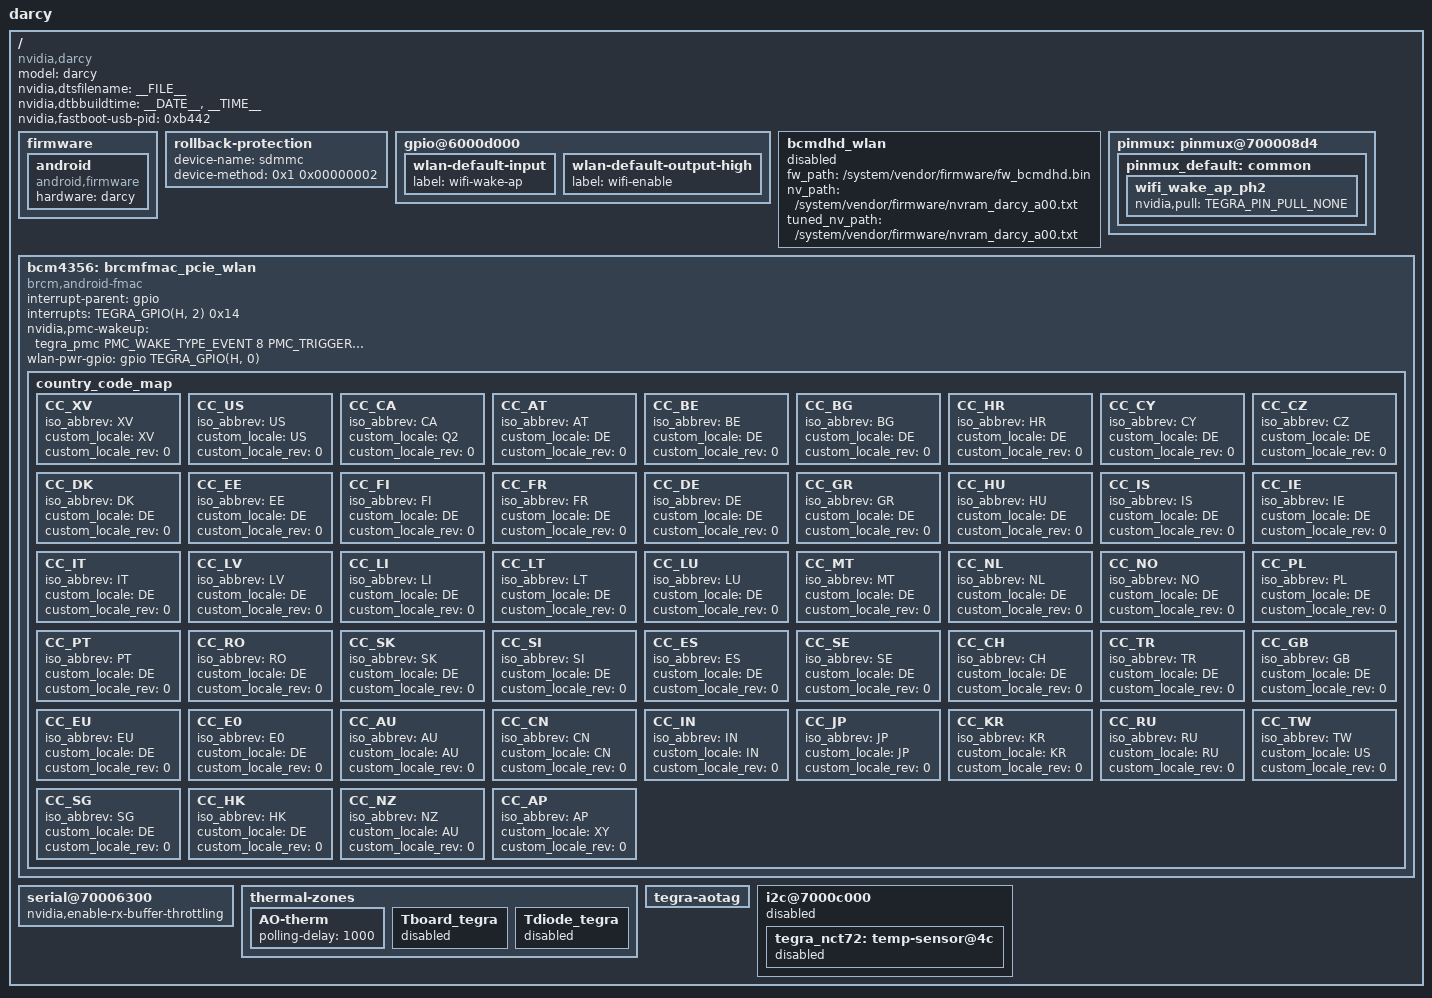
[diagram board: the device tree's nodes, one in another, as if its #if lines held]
/*
 * arch/arm64/boot/dts/tegra210b01-darcy-p2894-2551-b00-00.dts
 *
 * Copyright (c) 2018, NVIDIA CORPORATION.  All rights reserved.
 *
 * This program is free software; you can redistribute it and/or modify
 * it under the terms of the GNU General Public License as published by
 * the Free Software Foundation; version 2 of the License.
 *
 * This program is distributed in the hope that it will be useful, but WITHOUT
 * ANY WARRANTY; without even the implied warranty of MERCHANTABILITY or
 * FITNESS FOR A PARTICULAR PURPOSE.  See the GNU General Public License for
 * more details.
 *
 * You should have received a copy of the GNU General Public License along
 * with this program; if not, write to the Free Software Foundation, Inc.,
 * 51 Franklin Street, Fifth Floor, Boston, MA  02110-1301, USA.
 *
 */
#include "tegra210b01-darcy-p2894-common.dtsi"
#include "foster-platforms/tegra210-darcy-pinmux-p2894-0000-a00.dtsi"
#include "darcy-platforms/tegra210b01-darcy-power-tree-p2894-0000-a00.dtsi"
#include "darcy-platforms/tegra210b01-darcy-extcon-p2894-0000-a00.dtsi"
#include "darcy-platforms/tegra210b01-darcy-pcie.dtsi"

/ {
	model = "darcy";
	compatible = "nvidia,darcy", "nvidia,foster-e", "nvidia,tegra210b01";
	nvidia,dtsfilename = __FILE__;
	nvidia,dtbbuildtime = __DATE__, __TIME__;
	nvidia,fastboot-usb-pid = <0xb442>;

	firmware {
		android {
			compatible = "android,firmware";
			hardware = "darcy";
		};
	};

	rollback-protection {
		device-name = "sdmmc";
		device-method = <0x1 0x00000002>; /* type (0x1 = ioctl), argument */
		status = "okay";
	};

	gpio@6000d000 {
		wlan-default-input {
			label = "wifi-wake-ap";
		};
		wlan-default-output-high {
			label = "wifi-enable";
		};
	};

	bcmdhd_wlan {
		fw_path = "/system/vendor/firmware/fw_bcmdhd.bin";
		nv_path = "/system/vendor/firmware/nvram_darcy_a00.txt";
		tuned_nv_path = "/system/vendor/firmware/nvram_darcy_a00.txt";
		status = "disabled";
	};

	pinmux: pinmux@700008d4 {
		pinmux_default: common {
			wifi_wake_ap_ph2 {
				nvidia,pull = <TEGRA_PIN_PULL_NONE>;
			};
		};
	};

	bcm4356: brcmfmac_pcie_wlan {
		compatible = "brcm,android-fmac";
		interrupt-parent = <&gpio>;
		interrupts = <TEGRA_GPIO(H, 2) 0x14>;
		nvidia,pmc-wakeup = <&tegra_pmc
		PMC_WAKE_TYPE_EVENT 8 PMC_TRIGGER_TYPE_HIGH>;
		wlan-pwr-gpio = <&gpio TEGRA_GPIO(H, 0) 0>;
		status = "okay";
		country_code_map {
			CC_XV {
				iso_abbrev = "XV";
				custom_locale = "XV";
				custom_locale_rev = <0>;
			};
			CC_US {
				iso_abbrev = "US";
				custom_locale = "US";
				custom_locale_rev = <0>;
			};
			CC_CA {
				iso_abbrev = "CA";
				custom_locale = "Q2";
				custom_locale_rev = <0>;
			};
			CC_AT {
				iso_abbrev = "AT";
				custom_locale = "DE";
				custom_locale_rev = <0>;
			};
			CC_BE {
				iso_abbrev = "BE";
				custom_locale = "DE";
				custom_locale_rev = <0>;
			};
			CC_BG {
				iso_abbrev = "BG";
				custom_locale = "DE";
				custom_locale_rev = <0>;
			};
			CC_HR {
				iso_abbrev = "HR";
				custom_locale = "DE";
				custom_locale_rev = <0>;
			};
			CC_CY {
				iso_abbrev = "CY";
				custom_locale = "DE";
				custom_locale_rev = <0>;
			};
			CC_CZ {
				iso_abbrev = "CZ";
				custom_locale = "DE";
				custom_locale_rev = <0>;
			};
			CC_DK {
				iso_abbrev = "DK";
				custom_locale = "DE";
				custom_locale_rev = <0>;
			};
			CC_EE {
				iso_abbrev = "EE";
				custom_locale = "DE";
				custom_locale_rev = <0>;
			};
			CC_FI {
				iso_abbrev = "FI";
				custom_locale = "DE";
				custom_locale_rev = <0>;
			};
			CC_FR {
				iso_abbrev = "FR";
				custom_locale = "DE";
				custom_locale_rev = <0>;
			};
			CC_DE {
				iso_abbrev = "DE";
				custom_locale = "DE";
				custom_locale_rev = <0>;
			};
			CC_GR {
				iso_abbrev = "GR";
				custom_locale = "DE";
				custom_locale_rev = <0>;
			};
			CC_HU {
				iso_abbrev = "HU";
				custom_locale = "DE";
				custom_locale_rev = <0>;
			};
			CC_IS {
				iso_abbrev = "IS";
				custom_locale = "DE";
				custom_locale_rev = <0>;
			};
			CC_IE {
				iso_abbrev = "IE";
				custom_locale = "DE";
				custom_locale_rev = <0>;
			};
			CC_IT {
				iso_abbrev = "IT";
				custom_locale = "DE";
				custom_locale_rev = <0>;
			};
			CC_LV {
				iso_abbrev = "LV";
				custom_locale = "DE";
				custom_locale_rev = <0>;
			};
			CC_LI {
				iso_abbrev = "LI";
				custom_locale = "DE";
				custom_locale_rev = <0>;
			};
			CC_LT {
				iso_abbrev = "LT";
				custom_locale = "DE";
				custom_locale_rev = <0>;
			};
			CC_LU {
				iso_abbrev = "LU";
				custom_locale = "DE";
				custom_locale_rev = <0>;
			};
			CC_MT {
				iso_abbrev = "MT";
				custom_locale = "DE";
				custom_locale_rev = <0>;
			};
			CC_NL {
				iso_abbrev = "NL";
				custom_locale = "DE";
				custom_locale_rev = <0>;
			};
			CC_NO {
				iso_abbrev = "NO";
				custom_locale = "DE";
				custom_locale_rev = <0>;
			};
			CC_PL {
				iso_abbrev = "PL";
				custom_locale = "DE";
				custom_locale_rev = <0>;
			};
			CC_PT {
				iso_abbrev = "PT";
				custom_locale = "DE";
				custom_locale_rev = <0>;
			};
			CC_RO {
				iso_abbrev = "RO";
				custom_locale = "DE";
				custom_locale_rev = <0>;
			};
			CC_SK {
				iso_abbrev = "SK";
				custom_locale = "DE";
				custom_locale_rev = <0>;
			};
			CC_SI {
				iso_abbrev = "SI";
				custom_locale = "DE";
				custom_locale_rev = <0>;
			};
			CC_ES {
				iso_abbrev = "ES";
				custom_locale = "DE";
				custom_locale_rev = <0>;
			};
			CC_SE {
				iso_abbrev = "SE";
				custom_locale = "DE";
				custom_locale_rev = <0>;
			};
			CC_CH {
				iso_abbrev = "CH";
				custom_locale = "DE";
				custom_locale_rev = <0>;
			};
			CC_TR {
				iso_abbrev = "TR";
				custom_locale = "DE";
				custom_locale_rev = <0>;
			};
			CC_GB {
				iso_abbrev = "GB";
				custom_locale = "DE";
				custom_locale_rev = <0>;
			};
			CC_EU {
				iso_abbrev = "EU";
				custom_locale = "DE";
				custom_locale_rev = <0>;
			};
			CC_E0 {
				iso_abbrev = "E0";
				custom_locale = "DE";
				custom_locale_rev = <0>;
			};
			CC_AU {
				iso_abbrev = "AU";
				custom_locale = "AU";
				custom_locale_rev = <0>;
			};
			CC_CN {
				iso_abbrev = "CN";
				custom_locale = "CN";
				custom_locale_rev = <0>;
			};
			CC_IN {
				iso_abbrev = "IN";
				custom_locale = "IN";
				custom_locale_rev = <0>;
			};
			CC_JP {
				iso_abbrev = "JP";
				custom_locale = "JP";
				custom_locale_rev = <0>;
			};
			CC_KR {
				iso_abbrev = "KR";
				custom_locale = "KR";
				custom_locale_rev = <0>;
			};
			CC_RU {
				iso_abbrev = "RU";
				custom_locale = "RU";
				custom_locale_rev = <0>;
			};
			CC_TW {
				iso_abbrev = "TW";
				custom_locale = "US";
				custom_locale_rev = <0>;
			};
			CC_SG {
				iso_abbrev = "SG";
				custom_locale = "DE";
				custom_locale_rev = <0>;
			};
			CC_HK {
				iso_abbrev = "HK";
				custom_locale = "DE";
				custom_locale_rev = <0>;
			};
			CC_NZ {
				iso_abbrev = "NZ";
				custom_locale = "AU";
				custom_locale_rev = <0>;
			};
			CC_AP {
				iso_abbrev = "AP";
				custom_locale = "XY";
				custom_locale_rev = <0>;
			};
		};
	};

	serial@70006300 {
		nvidia,enable-rx-buffer-throttling;
	};

	thermal-zones {
		AO-therm {
			polling-delay = <1000>;
			status = "okay";
		};

		Tboard_tegra {
			status = "disabled";
		};

		Tdiode_tegra {
			status = "disabled";
		};
	};

	tegra-aotag {
		status = "okay";
	};

	i2c@7000c000 {
		status = "disabled";

		tegra_nct72: temp-sensor@4c {
			status = "disabled";
		};
	};
};

#if LINUX_VERSION >= 414
#include <tegra210-linux-4.14.dtsi>
#endif
